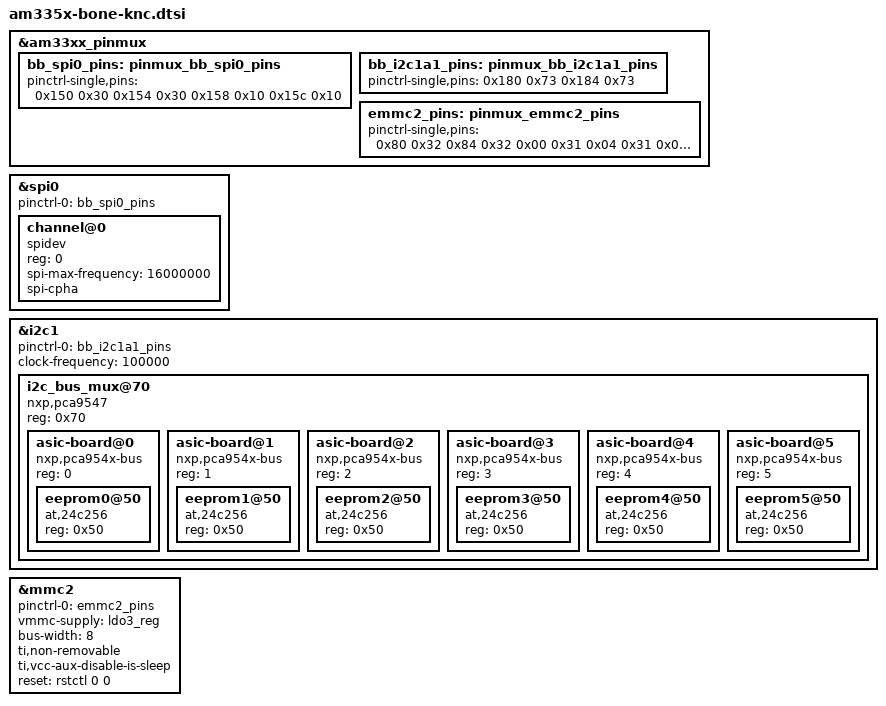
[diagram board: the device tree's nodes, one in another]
/*
 * Copyright (C) 2013 CircuitCo
 *
 * Virtual cape for SPI1 on connector pins P9.29 P9.31 P9.30 P9.28
 *
 * This program is free software; you can redistribute it and/or modify
 * it under the terms of the GNU General Public License version 2 as
 * published by the Free Software Foundation.
 */

&am33xx_pinmux {
    bb_spi0_pins: pinmux_bb_spi0_pins {
        pinctrl-single,pins = <
            0x150 0x30
            0x154 0x30
            0x158 0x10
            0x15c 0x10
        >;
    };
};


&spi0 {
    status = "okay";
    pinctrl-names = "default";
    pinctrl-0 = <&bb_spi0_pins>;
    
    #address-cells = <1>;
    #size-cells = <0>;

    channel@0 {
        #address-cells = <1>;
        #size-cells = <0>;

        compatible = "spidev";

        reg = <0>;
        spi-max-frequency = <16000000>;
        spi-cpha;
    };
/*
    channel@1 {
        #address-cells = <1>;
        #size-cells = <0>;

        compatible = "spidev";

        reg = <1>;
        spi-max-frequency = <16000000>;
    };
*/
};


&am33xx_pinmux {
    bb_i2c1a1_pins: pinmux_bb_i2c1a1_pins {
        pinctrl-single,pins = <
	    0x180 0x73	/* uart1_rxd.i2c1_sda, SLEWCTRL_SLOW | INPUT_PULLUP | MODE3 */
	    0x184 0x73	/* uart1_txdi2c1_scl, SLEWCTRL_SLOW | INPUT_PULLUP | MODE3 */
	>;
    };
};
	
&i2c1 {	/* i2c1 is numbered correctly */
    status = "okay";
    pinctrl-names = "default";
    pinctrl-0 = <&bb_i2c1a1_pins>;

    /* this is the configuration part */
    clock-frequency = <100000>;	

    #address-cells = <1>;
    #size-cells = <0>;

    i2c_bus_mux@70 {
        compatible = "nxp,pca9547";
	reg = <0x70>;
        #address-cells = <1>;
	#size-cells = <0>;

	asic-board@0 {
	    compatible = "nxp,pca954x-bus";
            #address-cells = <1>;
	    #size-cells = <0>;
	    reg = <0>;

	    eeprom0@50 {
                compatible = "at,24c256";
                reg = <0x50>;
            };
        };

        asic-board@1 {
            compatible = "nxp,pca954x-bus";
            #address-cells = <1>;
            #size-cells = <0>;
            reg = <1>;

            eeprom1@50 {
                compatible = "at,24c256";
                reg = <0x50>;
            };
        };

        asic-board@2 {
            compatible = "nxp,pca954x-bus";
            #address-cells = <1>;
            #size-cells = <0>;
            reg = <2>;

            eeprom2@50 {
                compatible = "at,24c256";
                reg = <0x50>;
            };
        };

        asic-board@3 {
            compatible = "nxp,pca954x-bus";
            #address-cells = <1>;
            #size-cells = <0>;
            reg = <3>;

            eeprom3@50 {
                compatible = "at,24c256";
                reg = <0x50>;
            };
        };

        asic-board@4 {
            compatible = "nxp,pca954x-bus";
            #address-cells = <1>;
            #size-cells = <0>;
            reg = <4>;

            eeprom4@50 {
                compatible = "at,24c256";
                reg = <0x50>;
            };
        };

        asic-board@5 {
            compatible = "nxp,pca954x-bus";
            #address-cells = <1>;
            #size-cells = <0>;
            reg = <5>;

            eeprom5@50 {
                compatible = "at,24c256";
                reg = <0x50>;
            };
        };
    };
};  
    

&am33xx_pinmux {
    emmc2_pins: pinmux_emmc2_pins {
        pinctrl-single,pins = <
            0x80 0x32	/* gpmc_csn1.mmc1_clk, INPUT_PULLUP | MODE2 */
            0x84 0x32	/* gpmc_csn2.mmc1_cmd, INPUT_PULLUP | MODE2 */
            0x00 0x31	/* gpmc_ad0.mmc1_dat0, INPUT_PULLUP | MODE1 */
            0x04 0x31	/* gpmc_ad1.mmc1_dat1, INPUT_PULLUP | MODE1 */
            0x08 0x31	/* gpmc_ad2.mmc1_dat2, INPUT_PULLUP | MODE1 */
            0x0c 0x31	/* gpmc_ad3.mmc1_dat3, INPUT_PULLUP | MODE1 */
            0x10 0x31	/* gpmc_ad4.mmc1_dat4, INPUT_PULLUP | MODE1 */
            0x14 0x31	/* gpmc_ad5.mmc1_dat5, INPUT_PULLUP | MODE1 */
            0x18 0x31	/* gpmc_ad6.mmc1_dat6, INPUT_PULLUP | MODE1 */
            0x1c 0x31	/* gpmc_ad7.mmc1_dat7, INPUT_PULLUP | MODE1 */
        >;
    };
};


&mmc2 {
    pinctrl-names = "default";
    pinctrl-0 = <&emmc2_pins>;	/* wrong numbering */
    vmmc-supply = <&ldo3_reg>;
    bus-width = <8>;
    ti,non-removable;
    status = "okay";
    ti,vcc-aux-disable-is-sleep;

    reset = <&rstctl 0 0>;
    reset-names = "eMMC_RSTn";
};
